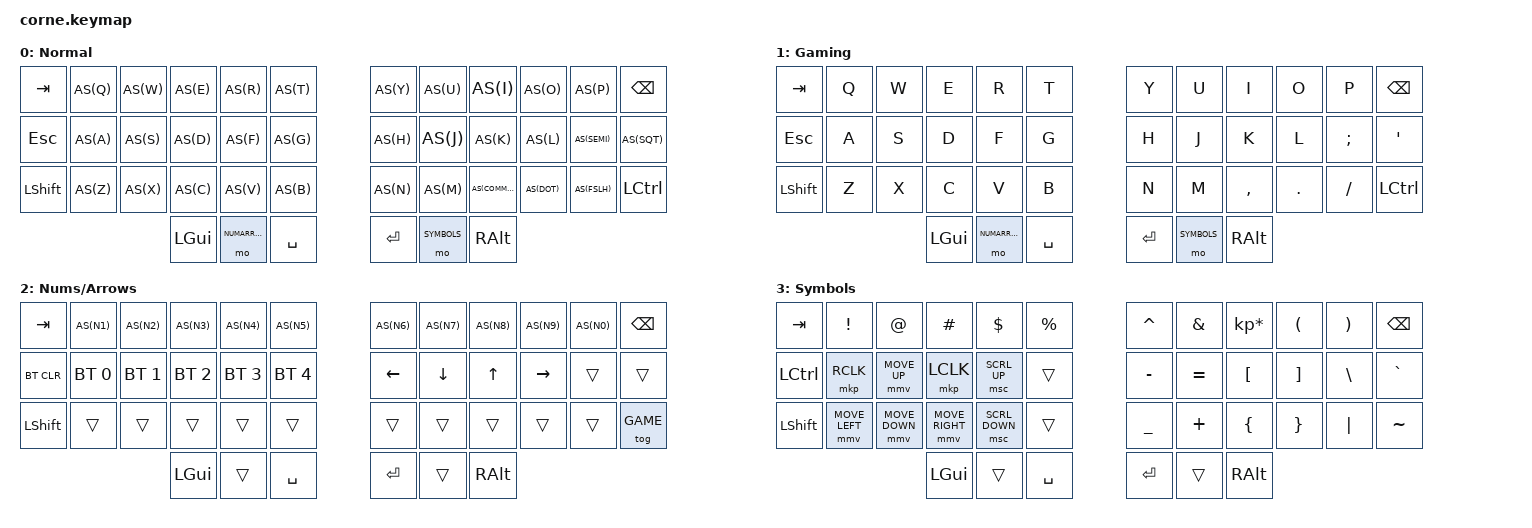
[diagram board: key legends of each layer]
/*
 * Copyright (c) 2020 The ZMK Contributors
 *
 * SPDX-License-Identifier: MIT
 */

#include <behaviors.dtsi>
#include <dt-bindings/zmk/keys.h>
#include <dt-bindings/zmk/bt.h>

// Double the default mouse-move speed (default is 600). Must be set before pointing.h.
#define ZMK_POINTING_DEFAULT_MOVE_VAL 1200
#include <dt-bindings/zmk/pointing.h>

#define AS(keycode) &as LS(keycode) keycode     // Autoshift Macro


#define NORMAL   0
#define GAME     1
#define NUMARROW 2
#define SYMBOLS  3

/ {

        behaviors {
            as: auto_shift {
                compatible = "zmk,behavior-hold-tap";
                label = "AUTO_SHIFT";
                #binding-cells = <2>;
                tapping_term_ms = <250>;
                quick_tap_ms = <0>;
                flavor = "tap-preferred";
                bindings = <&kp>, <&kp>;
            };
        };



        keymap {
                compatible = "zmk,keymap";

                default_layer {
                        label = "Normal";
                        bindings = <
   &kp TAB     AS(Q)   AS(W)     AS(E)     AS(R)     AS(T)   /*|*/   AS(Y)     AS(U)   AS(I)     AS(O)     AS(P)      &kp BSPC
   &kp ESC     AS(A)   AS(S)     AS(D)     AS(F)     AS(G)   /*|*/   AS(H)     AS(J)   AS(K)     AS(L)     AS(SEMI)   AS(SQT)
   &kp LSHFT   AS(Z)   AS(X)     AS(C)     AS(V)     AS(B)   /*|*/   AS(N)     AS(M)   AS(COMMA) AS(DOT)   AS(FSLH)   &kp LCTRL
                              &kp LGUI &mo NUMARROW &kp SPACE /*|*/  &kp RET    &mo SYMBOLS   &kp RALT
                        >;
                };

                gaming_layer {
                        label = "Gaming";
                        bindings = <
   &kp TAB     &kp Q   &kp W     &kp E     &kp R     &kp T   /*|*/   &kp Y     &kp U   &kp I     &kp O     &kp P      &kp BSPC
   &kp ESC     &kp A   &kp S     &kp D     &kp F     &kp G   /*|*/   &kp H     &kp J   &kp K     &kp L     &kp SEMI   &kp SQT
   &kp LSHFT   &kp Z   &kp X     &kp C     &kp V     &kp B   /*|*/   &kp N     &kp M   &kp COMMA &kp DOT   &kp FSLH   &kp LCTRL
                              &kp LGUI &mo NUMARROW &kp SPACE /*|*/  &kp RET    &mo SYMBOLS   &kp RALT
                        >;
                };

                lower_layer {
                        label = "Nums/Arrows";
                        bindings = <
   &kp TAB     AS(N1)        AS(N2)        AS(N3)        AS(N4)        AS(N5)              AS(N6)      AS(N7)      AS(N8)    AS(N9)      AS(N0)    &kp BSPC
   &bt BT_CLR  &bt BT_SEL 0  &bt BT_SEL 1  &bt BT_SEL 2  &bt BT_SEL 3  &bt BT_SEL 4        &kp LEFT    &kp DOWN    &kp UP    &kp RIGHT   &trans    &trans
   &kp LSHFT   &trans        &trans        &trans        &trans        &trans              &trans      &trans      &trans    &trans      &trans    &tog GAME
                                           &kp LGUI      &trans        &kp SPACE           &kp RET     &trans      &kp RALT
                        >;
                };

                raise_layer {
                        label = "Symbols";
                        bindings = <
   &kp  TAB    &kp EXCL         &kp AT          &kp HASH          &kp DLLR        &kp PRCNT      &kp CARET   &kp AMPS    &kp KP_MULTIPLY  &kp LPAR   &kp RPAR   &kp BSPC
   &kp LCTRL   &mkp RCLK        &mmv MOVE_UP    &mkp LCLK         &msc SCRL_UP    &trans         &kp MINUS   &kp EQUAL   &kp LBKT         &kp RBKT   &kp BSLH   &kp GRAVE
   &kp LSHFT   &mmv MOVE_LEFT   &mmv MOVE_DOWN  &mmv MOVE_RIGHT   &msc SCRL_DOWN  &trans         &kp UNDER   &kp PLUS    &kp LBRC         &kp RBRC   &kp PIPE   &kp TILDE
                                   &kp LGUI   &trans    &kp SPACE             &kp RET     &trans      &kp RALT
                        >;
                };

        };
};
